AUTOSAR XML (schema 00046)
package /COM/VECTOR/CFG/WORKFLOW/SYSDESC/SYNC
  system SYSTEM: category=ECU_EXTRACT
    system mapping MAPPINGS
    root-software-compositions:
      root sw composition prototype COMPOSITIONTYPE: flat-map=FLATMAP, software-composition=COMPOSITIONTYPE
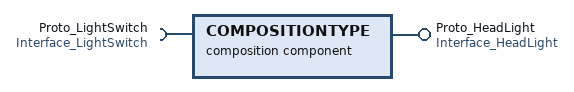
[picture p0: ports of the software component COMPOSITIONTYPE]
  composition sw component type COMPOSITIONTYPE  # UB:Derived from original system description
    provide port Proto_HeadLight: nonqueued-sender-com-spec=DE_HeadLight, provided-interface=Interface_HeadLight
    require port Proto_LightSwitch: nonqueued-receiver-com-spec{data-element=DE_LightSwitch, init-value=0}, required-interface=Interface_LightSwitch
    5 x component:
      ComM: type=ComM
      Det: type=Det
      EcuM: type=EcuM
      BswM: type=BswM
      MySWC: type=MySWC
    delegate MySWC.Proto_HeadLight <-> outer port Proto_HeadLight  # UB:Derived from original system description
    delegate MySWC.Proto_LightSwitch <-> outer port Proto_LightSwitch  # UB:Derived from original system description
  end to end protection set E2EPROTECTIONSET
  port interface mapping set PORTINTERFACEMAPPINGSET
